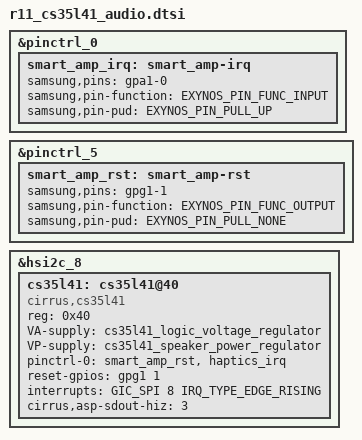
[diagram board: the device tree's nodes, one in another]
/*
 * Device Tree config for the CS35L41 chip - Smart amplifier
 */

#include <dt-bindings/interrupt-controller/irq.h>
#include <dt-bindings/interrupt-controller/arm-gic.h>

&pinctrl_0 {
	// Shared with haptics IC
	smart_amp_irq: smart_amp-irq {
		// gpio8
		samsung,pins = "gpa1-0";
		samsung,pin-function = <EXYNOS_PIN_FUNC_INPUT>;
		samsung,pin-pud = <EXYNOS_PIN_PULL_UP>;
	};
};

&pinctrl_5 {
	// GPIO95
	smart_amp_rst: smart_amp-rst {
		samsung,pins = "gpg1-1";
		samsung,pin-function = <EXYNOS_PIN_FUNC_OUTPUT>;
		samsung,pin-pud = <EXYNOS_PIN_PULL_NONE>;
	};
};

&hsi2c_8 {
	#address-cells = <1>;
	#size-cells = <0>;
	status = "ok";

	cs35l41: cs35l41@40 {
		compatible = "cirrus,cs35l41", "cirrus,cs35l40";
		reg = <0x40>;
		VA-supply = <&cs35l41_logic_voltage_regulator>;
		VP-supply = <&cs35l41_speaker_power_regulator>;

		pinctrl-names = "default";
		pinctrl-0 = <&smart_amp_rst &haptics_irq>;
		reset-gpios = <&gpg1 1 GPIO_ACTIVE_HIGH>;
		interrupts = <GIC_SPI 8 IRQ_TYPE_EDGE_RISING>;

		// cirrus,boost-peak-milliamp = <1600>;
		// cirrus,boost-ind-nanohenry = <1000>;
		// cirrus,boost-cap-microfarad = <30>;
		// cirrus,right-channel-amp;
		// Mode 3: Hi-Z during unused slots and while all transmit channels disabled
		cirrus,asp-sdout-hiz = <3>;
	};
};
